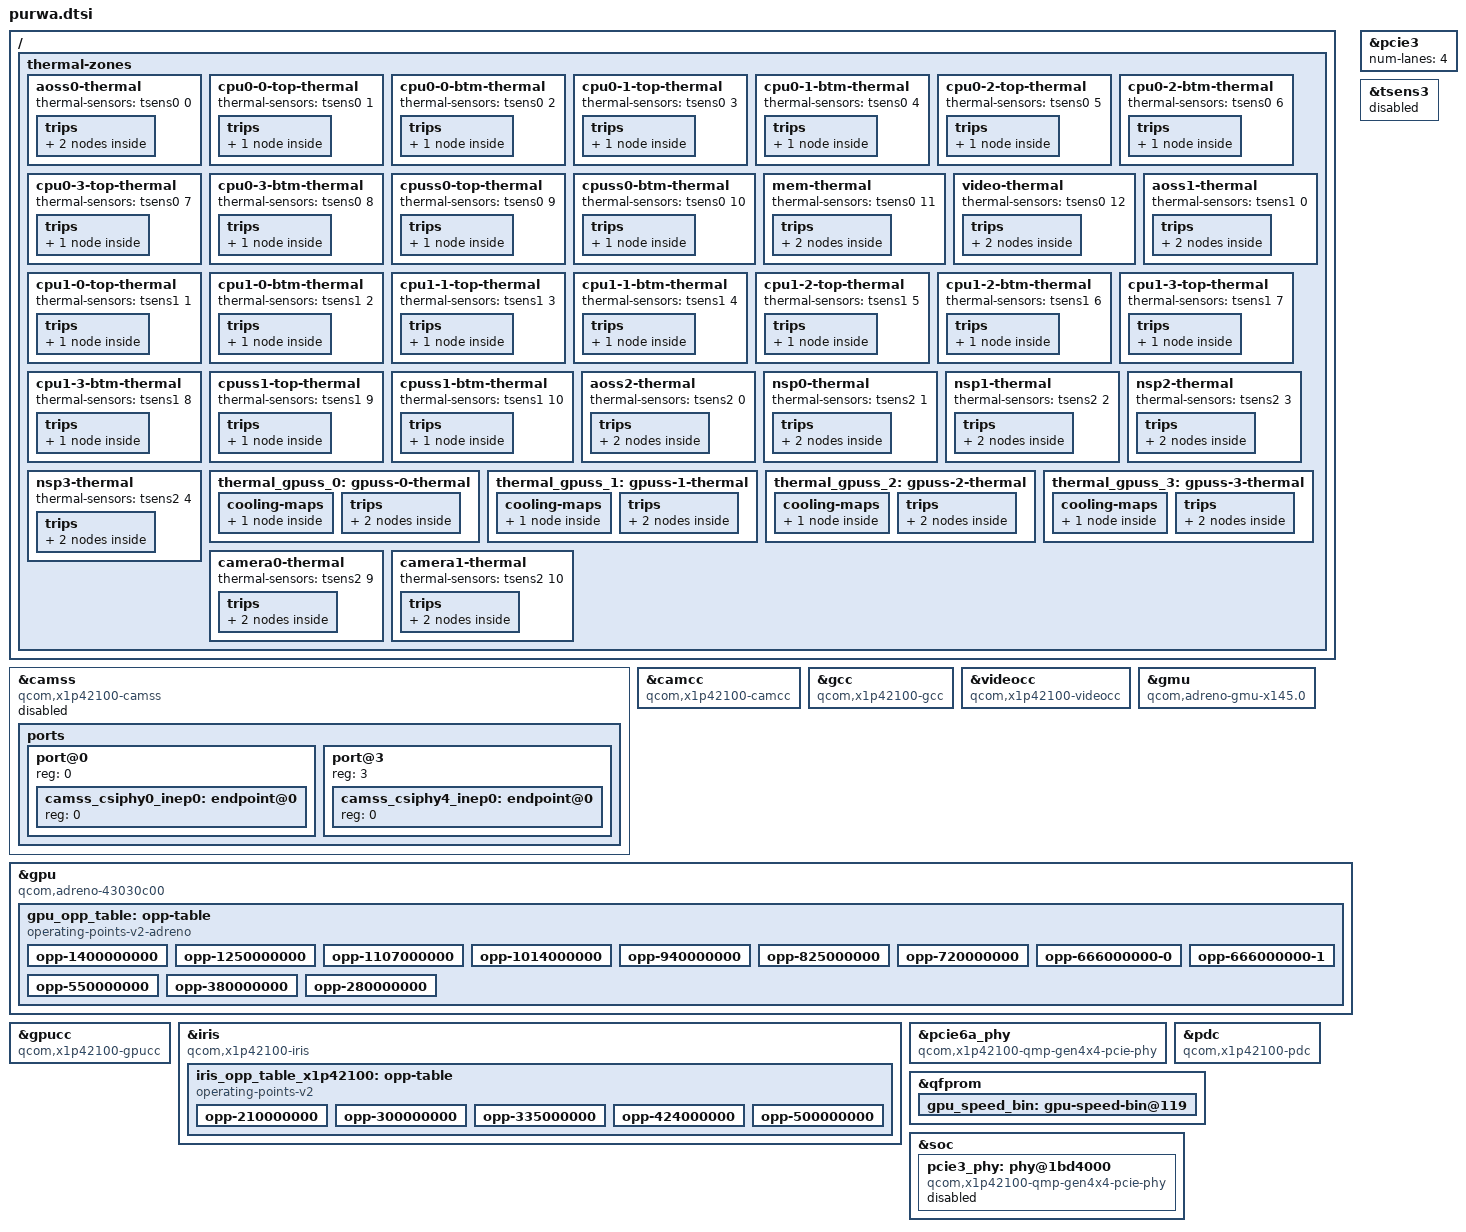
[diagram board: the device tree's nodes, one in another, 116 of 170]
// SPDX-License-Identifier: BSD-3-Clause
/*
 * Copyright (c) 2025 Qualcomm Innovation Center, Inc. All rights reserved.
 */

/* X1P42100 is heavily based on hamoa, with some meaningful differences */
#include "hamoa.dtsi"

#include <dt-bindings/clock/qcom,x1p42100-videocc.h>

/delete-node/ &bwmon_cluster0;
/delete-node/ &cluster_pd2;
/delete-node/ &cpu_map_cluster2;
/delete-node/ &cpu8;
/delete-node/ &cpu9;
/delete-node/ &cpu10;
/delete-node/ &cpu11;
/delete-node/ &cpu_pd8;
/delete-node/ &cpu_pd9;
/delete-node/ &cpu_pd10;
/delete-node/ &cpu_pd11;
/delete-node/ &csiphy1;
/delete-node/ &csiphy2;
/delete-node/ &gpu_opp_table;
/delete-node/ &gpu_speed_bin;
/delete-node/ &iris_opp_table;
/delete-node/ &pcie3_phy;
/delete-node/ &thermal_zones;
/delete-node/ &etm8;
/delete-node/ &etm9;
/delete-node/ &etm10;
/delete-node/ &etm11;
/delete-node/ &cluster2_funnel_l1;
/delete-node/ &cluster2_funnel_l2;
/delete-node/ &cluster2_etf;
/delete-node/ &cluster2_rep_2_0;
/delete-node/ &cluster2_rep_2_1;
/delete-node/ &cluster2_rep_2_2;
/delete-node/ &cluster2_rep_2_3;
/delete-node/ &apss_funnel_in2;

&camss {
	compatible = "qcom,x1p42100-camss";

	reg = <0 0x0acb7000 0 0x2000>,
	      <0 0x0acb9000 0 0x2000>,
	      <0 0x0acbb000 0 0x2000>,
	      <0 0x0acc6000 0 0x1000>,
	      <0 0x0acca000 0 0x1000>,
	      <0 0x0acb6000 0 0x1000>,
	      <0 0x0ace4000 0 0x1000>,
	      <0 0x0acec000 0 0x4000>,
	      <0 0x0acf6000 0 0x1000>,
	      <0 0x0acf7000 0 0x1000>,
	      <0 0x0acf8000 0 0x1000>,
	      <0 0x0ac62000 0 0x4000>,
	      <0 0x0acc7000 0 0x2000>,
	      <0 0x0accb000 0 0x2000>;

	reg-names = "csid0",
		    "csid1",
		    "csid2",
		    "csid_lite0",
		    "csid_lite1",
		    "csid_wrapper",
		    "csiphy0",
		    "csiphy4",
		    "csitpg0",
		    "csitpg1",
		    "csitpg2",
		    "vfe0",
		    "vfe_lite0",
		    "vfe_lite1";

	interrupts = <GIC_SPI 464 IRQ_TYPE_EDGE_RISING>,
		     <GIC_SPI 466 IRQ_TYPE_EDGE_RISING>,
		     <GIC_SPI 431 IRQ_TYPE_EDGE_RISING>,
		     <GIC_SPI 468 IRQ_TYPE_EDGE_RISING>,
		     <GIC_SPI 359 IRQ_TYPE_EDGE_RISING>,
		     <GIC_SPI 477 IRQ_TYPE_EDGE_RISING>,
		     <GIC_SPI 122 IRQ_TYPE_EDGE_RISING>,
		     <GIC_SPI 465 IRQ_TYPE_EDGE_RISING>,
		     <GIC_SPI 469 IRQ_TYPE_EDGE_RISING>,
		     <GIC_SPI 360 IRQ_TYPE_EDGE_RISING>;

	interrupt-names = "csid0",
			  "csid1",
			  "csid2",
			  "csid_lite0",
			  "csid_lite1",
			  "csiphy0",
			  "csiphy4",
			  "vfe0",
			  "vfe_lite0",
			  "vfe_lite1";

	clocks = <&camcc CAM_CC_CAMNOC_AXI_NRT_CLK>,
		 <&camcc CAM_CC_CAMNOC_AXI_RT_CLK>,
		 <&camcc CAM_CC_CORE_AHB_CLK>,
		 <&camcc CAM_CC_CPAS_AHB_CLK>,
		 <&camcc CAM_CC_CPAS_FAST_AHB_CLK>,
		 <&camcc CAM_CC_CPAS_IFE_0_CLK>,
		 <&camcc CAM_CC_CPAS_IFE_LITE_CLK>,
		 <&camcc CAM_CC_CPHY_RX_CLK_SRC>,
		 <&camcc CAM_CC_CSID_CLK>,
		 <&camcc CAM_CC_CSID_CSIPHY_RX_CLK>,
		 <&camcc CAM_CC_CSIPHY0_CLK>,
		 <&camcc CAM_CC_CSI0PHYTIMER_CLK>,
		 <&camcc CAM_CC_CSIPHY4_CLK>,
		 <&camcc CAM_CC_CSI4PHYTIMER_CLK>,
		 <&gcc GCC_CAMERA_HF_AXI_CLK>,
		 <&gcc GCC_CAMERA_SF_AXI_CLK>,
		 <&camcc CAM_CC_IFE_0_CLK>,
		 <&camcc CAM_CC_IFE_0_FAST_AHB_CLK>,
		 <&camcc CAM_CC_IFE_LITE_CLK>,
		 <&camcc CAM_CC_IFE_LITE_AHB_CLK>,
		 <&camcc CAM_CC_IFE_LITE_CPHY_RX_CLK>,
		 <&camcc CAM_CC_IFE_LITE_CSID_CLK>;

	clock-names = "camnoc_nrt_axi",
		      "camnoc_rt_axi",
		      "core_ahb",
		      "cpas_ahb",
		      "cpas_fast_ahb",
		      "cpas_vfe0",
		      "cpas_vfe_lite",
		      "cphy_rx_clk_src",
		      "csid",
		      "csid_csiphy_rx",
		      "csiphy0",
		      "csiphy0_timer",
		      "csiphy4",
		      "csiphy4_timer",
		      "gcc_axi_hf",
		      "gcc_axi_sf",
		      "vfe0",
		      "vfe0_fast_ahb",
		      "vfe_lite",
		      "vfe_lite_ahb",
		      "vfe_lite_cphy_rx",
		      "vfe_lite_csid";

	interconnects = <&gem_noc MASTER_APPSS_PROC QCOM_ICC_TAG_ACTIVE_ONLY
			 &config_noc SLAVE_CAMERA_CFG QCOM_ICC_TAG_ACTIVE_ONLY>,
			<&mmss_noc MASTER_CAMNOC_HF QCOM_ICC_TAG_ALWAYS
			 &mc_virt SLAVE_EBI1 QCOM_ICC_TAG_ALWAYS>,
			<&mmss_noc MASTER_CAMNOC_SF QCOM_ICC_TAG_ALWAYS
			 &mc_virt SLAVE_EBI1 QCOM_ICC_TAG_ALWAYS>,
			<&mmss_noc MASTER_CAMNOC_ICP QCOM_ICC_TAG_ALWAYS
			 &mc_virt SLAVE_EBI1 QCOM_ICC_TAG_ALWAYS>;
	interconnect-names = "ahb",
			     "hf_mnoc",
			     "sf_mnoc",
			     "sf_icp_mnoc";

	iommus = <&apps_smmu 0x800 0x60>,
		 <&apps_smmu 0x860 0x60>,
		 <&apps_smmu 0x1860 0x60>,
		 <&apps_smmu 0x18e0 0x00>,
		 <&apps_smmu 0x19a0 0x20>;

	power-domains = <&camcc CAM_CC_IFE_0_GDSC>,
			<&camcc CAM_CC_TITAN_TOP_GDSC>;
	power-domain-names = "ife0",
			     "top";

	phys = <&csiphy0 PHY_TYPE_DPHY>,
	       <&csiphy4 PHY_TYPE_DPHY>;
	phy-names = "csiphy0",
		    "csiphy4";

	status = "disabled";

	ports {
		#address-cells = <1>;
		#size-cells = <0>;

		port@0 {
			reg = <0>;
			#address-cells = <1>;
			#size-cells = <0>;
			camss_csiphy0_inep0: endpoint@0 {
				reg = <0>;
			};
		};

		port@3 {
			reg = <3>;
			#address-cells = <1>;
			#size-cells = <0>;
			camss_csiphy4_inep0: endpoint@0 {
				reg = <0>;
			};
		};
	};
};

&camcc {
	compatible = "qcom,x1p42100-camcc";
};

&gcc {
	compatible = "qcom,x1p42100-gcc", "qcom,x1e80100-gcc";
};

&videocc {
	compatible = "qcom,x1p42100-videocc";
};

&gmu {
	compatible = "qcom,adreno-gmu-x145.0", "qcom,adreno-gmu";
};

&gpu {
	compatible = "qcom,adreno-43030c00", "qcom,adreno";

	iommus = <&adreno_smmu 0 0x0>;

	nvmem-cells = <&gpu_speed_bin>;
	nvmem-cell-names = "speed_bin";

	gpu_opp_table: opp-table {
		compatible = "operating-points-v2-adreno", "operating-points-v2";

		opp-1400000000 {
			opp-hz = /bits/ 64 <1400000000>;
			opp-level = <RPMH_REGULATOR_LEVEL_TURBO_L4>;
			opp-peak-kBps = <16500000>;
			qcom,opp-acd-level = <0xa8295ffd>;
			opp-supported-hw = <0x3>;
		};

		opp-1250000000 {
			opp-hz = /bits/ 64 <1250000000>;
			opp-level = <RPMH_REGULATOR_LEVEL_TURBO_L3>;
			opp-peak-kBps = <16500000>;
			qcom,opp-acd-level = <0x882a5ffd>;
			opp-supported-hw = <0x7>;
		};

		opp-1107000000 {
			opp-hz = /bits/ 64 <1107000000>;
			opp-level = <RPMH_REGULATOR_LEVEL_TURBO_L1>;
			opp-peak-kBps = <16500000>;
			qcom,opp-acd-level = <0x882a5ffd>;
			opp-supported-hw = <0xf>;
		};

		opp-1014000000 {
			opp-hz = /bits/ 64 <1014000000>;
			opp-level = <RPMH_REGULATOR_LEVEL_TURBO>;
			opp-peak-kBps = <14398438>;
			qcom,opp-acd-level = <0xa82a5ffd>;
			opp-supported-hw = <0xf>;
		};

		opp-940000000 {
			opp-hz = /bits/ 64 <940000000>;
			opp-level = <RPMH_REGULATOR_LEVEL_NOM_L1>;
			opp-peak-kBps = <14398438>;
			qcom,opp-acd-level = <0xa82a5ffd>;
			opp-supported-hw = <0xf>;
		};

		opp-825000000 {
			opp-hz = /bits/ 64 <825000000>;
			opp-level = <RPMH_REGULATOR_LEVEL_NOM>;
			opp-peak-kBps = <12449219>;
			qcom,opp-acd-level = <0x882b5ffd>;
			opp-supported-hw = <0xf>;
		};

		opp-720000000 {
			opp-hz = /bits/ 64 <720000000>;
			opp-level = <RPMH_REGULATOR_LEVEL_SVS_L2>;
			opp-peak-kBps = <10687500>;
			qcom,opp-acd-level = <0xa82c5ffd>;
			opp-supported-hw = <0xf>;
		};

		opp-666000000-0 {
			opp-hz = /bits/ 64 <666000000>;
			opp-level = <RPMH_REGULATOR_LEVEL_SVS_L1>;
			opp-peak-kBps = <8171875>;
			qcom,opp-acd-level = <0xa82d5ffd>;
			opp-supported-hw = <0xf>;
		};

		/* Only applicable for SKUs which has 666Mhz as Fmax */
		opp-666000000-1 {
			opp-hz = /bits/ 64 <666000000>;
			opp-level = <RPMH_REGULATOR_LEVEL_SVS_L1>;
			opp-peak-kBps = <16500000>;
			qcom,opp-acd-level = <0xa82d5ffd>;
			opp-supported-hw = <0x10>;
		};

		opp-550000000 {
			opp-hz = /bits/ 64 <550000000>;
			opp-level = <RPMH_REGULATOR_LEVEL_SVS>;
			opp-peak-kBps = <6074219>;
			qcom,opp-acd-level = <0x882e5ffd>;
			opp-supported-hw = <0x1f>;
		};

		opp-380000000 {
			opp-hz = /bits/ 64 <380000000>;
			opp-level = <RPMH_REGULATOR_LEVEL_LOW_SVS>;
			opp-peak-kBps = <3000000>;
			qcom,opp-acd-level = <0xc82f5ffd>;
			opp-supported-hw = <0x1f>;
		};

		opp-280000000 {
			opp-hz = /bits/ 64 <280000000>;
			opp-level = <RPMH_REGULATOR_LEVEL_LOW_SVS_D1>;
			opp-peak-kBps = <2136719>;
			qcom,opp-acd-level = <0xc82f5ffd>;
			opp-supported-hw = <0x1f>;
		};
	};

};

&gpucc {
	compatible = "qcom,x1p42100-gpucc";
};

&iris {
	compatible = "qcom,x1p42100-iris";

	clocks = <&gcc GCC_VIDEO_AXI0_CLK>,
		 <&videocc VIDEO_CC_MVS0C_CLK>,
		 <&videocc VIDEO_CC_MVS0_CLK>,
		 <&videocc VIDEO_CC_MVS0_BSE_CLK>;
	clock-names = "iface",
		      "core",
		      "vcodec0_core",
		      "vcodec0_bse";

	operating-points-v2 = <&iris_opp_table_x1p42100>;

	iris_opp_table_x1p42100: opp-table {
		compatible = "operating-points-v2";

		opp-210000000 {
			opp-hz = /bits/ 64 <210000000 105000000>;
			required-opps = <&rpmhpd_opp_low_svs_d1>,
					<&rpmhpd_opp_low_svs>;
		};

		opp-300000000 {
			opp-hz = /bits/ 64 <300000000 150000000>;
			required-opps = <&rpmhpd_opp_low_svs_d1>,
					<&rpmhpd_opp_svs>;
		};

		opp-335000000 {
			opp-hz = /bits/ 64 <335000000 167500000>;
			required-opps = <&rpmhpd_opp_svs>,
					<&rpmhpd_opp_svs_l1>;
		};

		opp-424000000 {
			opp-hz = /bits/ 64 <424000000 212000000>;
			required-opps = <&rpmhpd_opp_svs>,
					<&rpmhpd_opp_nom>;
		};

		opp-500000000 {
			opp-hz = /bits/ 64 <500000000 250000000>;
			required-opps = <&rpmhpd_opp_svs>,
					<&rpmhpd_opp_turbo>;
		};
	};
};

/* PCIe3 has half the lanes compared to X1E80100 */
&pcie3 {
	num-lanes = <4>;
};

&pcie6a_phy {
	compatible = "qcom,x1p42100-qmp-gen4x4-pcie-phy";
};

&pdc {
	compatible = "qcom,x1p42100-pdc", "qcom,pdc";
};

&qfprom {
	gpu_speed_bin: gpu-speed-bin@119 {
		reg = <0x119 0x2>;
		bits = <7 9>;
	};
};

&soc {
	/* The PCIe3 PHY on X1P42100 uses a different IP block */
	pcie3_phy: phy@1bd4000 {
		compatible = "qcom,x1p42100-qmp-gen4x4-pcie-phy";
		reg = <0x0 0x01bd4000 0x0 0x2000>,
		      <0x0 0x01bd6000 0x0 0x2000>;

		clocks = <&gcc GCC_PCIE_3_PHY_AUX_CLK>,
			 <&gcc GCC_PCIE_3_CFG_AHB_CLK>,
			 <&tcsr TCSR_PCIE_8L_CLKREF_EN>,
			 <&gcc GCC_PCIE_3_PHY_RCHNG_CLK>,
			 <&gcc GCC_PCIE_3_PIPE_CLK>,
			 <&gcc GCC_PCIE_3_PIPEDIV2_CLK>;
		clock-names = "aux",
			      "cfg_ahb",
			      "ref",
			      "rchng",
			      "pipe",
			      "pipediv2";

		resets = <&gcc GCC_PCIE_3_PHY_BCR>,
			 <&gcc GCC_PCIE_3_NOCSR_COM_PHY_BCR>;
		reset-names = "phy",
			      "phy_nocsr";

		assigned-clocks = <&gcc GCC_PCIE_3_PHY_RCHNG_CLK>;
		assigned-clock-rates = <100000000>;

		power-domains = <&gcc GCC_PCIE_3_PHY_GDSC>;

		#clock-cells = <0>;
		clock-output-names = "pcie3_pipe_clk";

		#phy-cells = <0>;

		status = "disabled";
	};
};

/* While physically present, this controller is left unconfigured and unused */
&tsens3 {
	status = "disabled";
};

/ {
	thermal-zones {
		aoss0-thermal {
			thermal-sensors = <&tsens0 0>;

			trips {
				trip-point0 {
					temperature = <90000>;
					hysteresis = <2000>;
					type = "hot";
				};

				trip-point1 {
					temperature = <115000>;
					hysteresis = <1000>;
					type = "critical";
				};
			};
		};

		cpu0-0-top-thermal {
			thermal-sensors = <&tsens0 1>;

			trips {
				trip-point0 {
					temperature = <115000>;
					hysteresis = <1000>;
					type = "critical";
				};
			};
		};

		cpu0-0-btm-thermal {
			thermal-sensors = <&tsens0 2>;

			trips {
				trip-point0 {
					temperature = <115000>;
					hysteresis = <1000>;
					type = "critical";
				};
			};
		};

		cpu0-1-top-thermal {
			thermal-sensors = <&tsens0 3>;

			trips {
				trip-point0 {
					temperature = <115000>;
					hysteresis = <1000>;
					type = "critical";
				};
			};
		};

		cpu0-1-btm-thermal {
			thermal-sensors = <&tsens0 4>;

			trips {
				trip-point0 {
					temperature = <115000>;
					hysteresis = <1000>;
					type = "critical";
				};
			};
		};

		cpu0-2-top-thermal {
			thermal-sensors = <&tsens0 5>;

			trips {
				trip-point0 {
					temperature = <115000>;
					hysteresis = <1000>;
					type = "critical";
				};
			};
		};

		cpu0-2-btm-thermal {
			thermal-sensors = <&tsens0 6>;

			trips {
				trip-point0 {
					temperature = <115000>;
					hysteresis = <1000>;
					type = "critical";
				};
			};
		};

		cpu0-3-top-thermal {
			thermal-sensors = <&tsens0 7>;

			trips {
				trip-point0 {
					temperature = <115000>;
					hysteresis = <1000>;
					type = "critical";
				};
			};
		};

		cpu0-3-btm-thermal {
			thermal-sensors = <&tsens0 8>;

			trips {
				trip-point0 {
					temperature = <115000>;
					hysteresis = <1000>;
					type = "critical";
				};
			};
		};

		cpuss0-top-thermal {
			thermal-sensors = <&tsens0 9>;

			trips {
				trip-point0 {
					temperature = <115000>;
					hysteresis = <1000>;
					type = "critical";
				};
			};
		};

		cpuss0-btm-thermal {
			thermal-sensors = <&tsens0 10>;

			trips {
				trip-point0 {
					temperature = <115000>;
					hysteresis = <1000>;
					type = "critical";
				};
			};
		};

		mem-thermal {
			thermal-sensors = <&tsens0 11>;

			trips {
				trip-point0 {
					temperature = <90000>;
					hysteresis = <2000>;
					type = "hot";
				};

				trip-point1 {
					temperature = <115000>;
					hysteresis = <0>;
					type = "critical";
				};
			};
		};

		video-thermal {
			thermal-sensors = <&tsens0 12>;

			trips {
				trip-point0 {
					temperature = <90000>;
					hysteresis = <2000>;
					type = "hot";
				};

				trip-point1 {
					temperature = <115000>;
					hysteresis = <1000>;
					type = "critical";
				};
			};
		};

		aoss1-thermal {
			thermal-sensors = <&tsens1 0>;

			trips {
				trip-point0 {
					temperature = <90000>;
					hysteresis = <2000>;
					type = "hot";
				};

				trip-point1 {
					temperature = <115000>;
					hysteresis = <1000>;
					type = "critical";
				};
			};
		};

		cpu1-0-top-thermal {
			thermal-sensors = <&tsens1 1>;

			trips {
				trip-point0 {
					temperature = <115000>;
					hysteresis = <1000>;
					type = "critical";
				};
			};
		};

		cpu1-0-btm-thermal {
			thermal-sensors = <&tsens1 2>;

			trips {
				trip-point0 {
					temperature = <115000>;
					hysteresis = <1000>;
					type = "critical";
				};
			};
		};

		cpu1-1-top-thermal {
			thermal-sensors = <&tsens1 3>;

			trips {
				trip-point0 {
					temperature = <115000>;
					hysteresis = <1000>;
					type = "critical";
				};
			};
		};

		cpu1-1-btm-thermal {
			thermal-sensors = <&tsens1 4>;

			trips {
				trip-point0 {
					temperature = <115000>;
					hysteresis = <1000>;
					type = "critical";
				};
			};
		};

		cpu1-2-top-thermal {
			thermal-sensors = <&tsens1 5>;

			trips {
				trip-point0 {
					temperature = <115000>;
					hysteresis = <1000>;
					type = "critical";
				};
			};
		};

		cpu1-2-btm-thermal {
			thermal-sensors = <&tsens1 6>;

			trips {
				trip-point0 {
					temperature = <115000>;
					hysteresis = <1000>;
					type = "critical";
				};
			};
		};

		cpu1-3-top-thermal {
			thermal-sensors = <&tsens1 7>;

			trips {
				trip-point0 {
					temperature = <115000>;
					hysteresis = <1000>;
					type = "critical";
				};
			};
		};

		cpu1-3-btm-thermal {
			thermal-sensors = <&tsens1 8>;

			trips {
				trip-point0 {
					temperature = <115000>;
					hysteresis = <1000>;
					type = "critical";
				};
			};
		};

		cpuss1-top-thermal {
			thermal-sensors = <&tsens1 9>;

			trips {
				trip-point0 {
					temperature = <115000>;
					hysteresis = <1000>;
					type = "critical";
				};
			};
		};

		cpuss1-btm-thermal {
			thermal-sensors = <&tsens1 10>;

			trips {
				trip-point0 {
					temperature = <115000>;
					hysteresis = <1000>;
					type = "critical";
				};
			};
		};

		aoss2-thermal {
			thermal-sensors = <&tsens2 0>;

			trips {
				trip-point0 {
					temperature = <90000>;
					hysteresis = <2000>;
					type = "hot";
				};

				trip-point1 {
					temperature = <115000>;
					hysteresis = <1000>;
					type = "critical";
				};
			};
		};

		nsp0-thermal {
			thermal-sensors = <&tsens2 1>;

			trips {
				trip-point0 {
					temperature = <90000>;
					hysteresis = <2000>;
					type = "hot";
				};

				trip-point1 {
					temperature = <115000>;
					hysteresis = <1000>;
					type = "critical";
				};
			};
		};

		nsp1-thermal {
			thermal-sensors = <&tsens2 2>;

			trips {
				trip-point0 {
					temperature = <90000>;
					hysteresis = <2000>;
					type = "hot";
				};

				trip-point1 {
					temperature = <115000>;
					hysteresis = <1000>;
					type = "critical";
				};
			};
		};

		nsp2-thermal {
			thermal-sensors = <&tsens2 3>;

			trips {
				trip-point0 {
					temperature = <90000>;
					hysteresis = <2000>;
					type = "hot";
				};

				trip-point1 {
					temperature = <115000>;
					hysteresis = <1000>;
					type = "critical";
				};
			};
		};

		nsp3-thermal {
			thermal-sensors = <&tsens2 4>;

			trips {
				trip-point0 {
					temperature = <90000>;
					hysteresis = <2000>;
					type = "hot";
				};

				trip-point1 {
					temperature = <115000>;
					hysteresis = <1000>;
					type = "critical";
				};
			};
		};

		thermal_gpuss_0: gpuss-0-thermal {
			polling-delay-passive = <200>;

			thermal-sensors = <&tsens2 5>;

			cooling-maps {
				map0 {
					trip = <&gpuss0_alert0>;
					cooling-device = <&gpu THERMAL_NO_LIMIT THERMAL_NO_LIMIT>;
				};
			};

			trips {
				gpuss0_alert0: trip-point0 {
					temperature = <95000>;
					hysteresis = <1000>;
					type = "passive";
				};

				trip-point1 {
					temperature = <115000>;
					hysteresis = <1000>;
					type = "critical";
				};
			};
		};

		thermal_gpuss_1: gpuss-1-thermal {
			polling-delay-passive = <200>;

			thermal-sensors = <&tsens2 6>;

			cooling-maps {
				map0 {
					trip = <&gpuss1_alert0>;
					cooling-device = <&gpu THERMAL_NO_LIMIT THERMAL_NO_LIMIT>;
				};
			};

			trips {
				gpuss1_alert0: trip-point0 {
					temperature = <95000>;
					hysteresis = <1000>;
					type = "passive";
				};

				trip-point1 {
					temperature = <115000>;
					hysteresis = <1000>;
					type = "critical";
				};
			};
		};

		thermal_gpuss_2: gpuss-2-thermal {
			polling-delay-passive = <200>;

			thermal-sensors = <&tsens2 7>;

			cooling-maps {
				map0 {
					trip = <&gpuss2_alert0>;
					cooling-device = <&gpu THERMAL_NO_LIMIT THERMAL_NO_LIMIT>;
				};
			};

			trips {
				gpuss2_alert0: trip-point0 {
					temperature = <95000>;
					hysteresis = <1000>;
					type = "passive";
				};

				trip-point1 {
					temperature = <115000>;
					hysteresis = <1000>;
					type = "critical";
				};
			};
		};

		thermal_gpuss_3: gpuss-3-thermal {
			polling-delay-passive = <200>;

			thermal-sensors = <&tsens2 8>;

			cooling-maps {
				map0 {
					trip = <&gpuss3_alert0>;
					cooling-device = <&gpu THERMAL_NO_LIMIT THERMAL_NO_LIMIT>;
				};
			};

			trips {
				gpuss3_alert0: trip-point0 {
					temperature = <95000>;
					hysteresis = <1000>;
					type = "passive";
				};

				trip-point1 {
					temperature = <115000>;
					hysteresis = <1000>;
					type = "critical";
				};
			};
		};

		camera0-thermal {
			thermal-sensors = <&tsens2 9>;

			trips {
				trip-point0 {
					temperature = <90000>;
					hysteresis = <2000>;
					type = "hot";
				};

				trip-point1 {
					temperature = <115000>;
					hysteresis = <1000>;
					type = "critical";
				};
			};
		};

		camera1-thermal {
			thermal-sensors = <&tsens2 10>;

			trips {
				trip-point0 {
					temperature = <90000>;
					hysteresis = <2000>;
					type = "hot";
				};

				trip-point1 {
					temperature = <115000>;
					hysteresis = <1000>;
					type = "critical";
				};
			};
		};
	};
};
